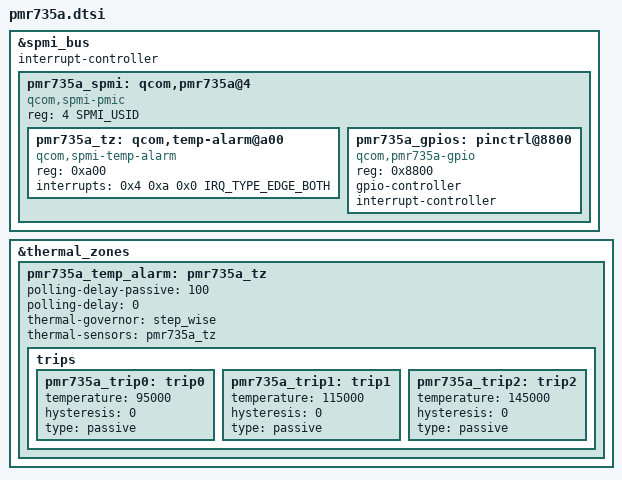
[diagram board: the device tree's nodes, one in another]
#include <dt-bindings/interrupt-controller/irq.h>
#include <dt-bindings/spmi/spmi.h>

&spmi_bus {
	#address-cells = <2>;
	#size-cells = <0>;
	interrupt-controller;
	#interrupt-cells = <4>;

	pmr735a_spmi: qcom,pmr735a@4 {
		compatible = "qcom,spmi-pmic";
		reg = <4 SPMI_USID>;
		#address-cells = <1>;
		#size-cells = <0>;

		pmr735a_tz: qcom,temp-alarm@a00 {
			compatible = "qcom,spmi-temp-alarm";
			reg = <0xa00>;
			interrupts = <0x4 0xa 0x0 IRQ_TYPE_EDGE_BOTH>;
			#thermal-sensor-cells = <0>;
		};

		pmr735a_gpios: pinctrl@8800 {
			compatible = "qcom,pmr735a-gpio";
			reg = <0x8800>;
			gpio-controller;
			#gpio-cells = <2>;
			interrupt-controller;
			#interrupt-cells = <2>;
		};
	};
};

&thermal_zones {
	pmr735a_temp_alarm: pmr735a_tz {
		polling-delay-passive = <100>;
		polling-delay = <0>;
		thermal-governor = "step_wise";
		thermal-sensors = <&pmr735a_tz>;

		trips {
			pmr735a_trip0: trip0 {
				temperature = <95000>;
				hysteresis = <0>;
				type = "passive";
			};

			pmr735a_trip1: trip1 {
				temperature = <115000>;
				hysteresis = <0>;
				type = "passive";
			};

			pmr735a_trip2: trip2 {
				temperature = <145000>;
				hysteresis = <0>;
				type = "passive";
			};
		};
	};
};
